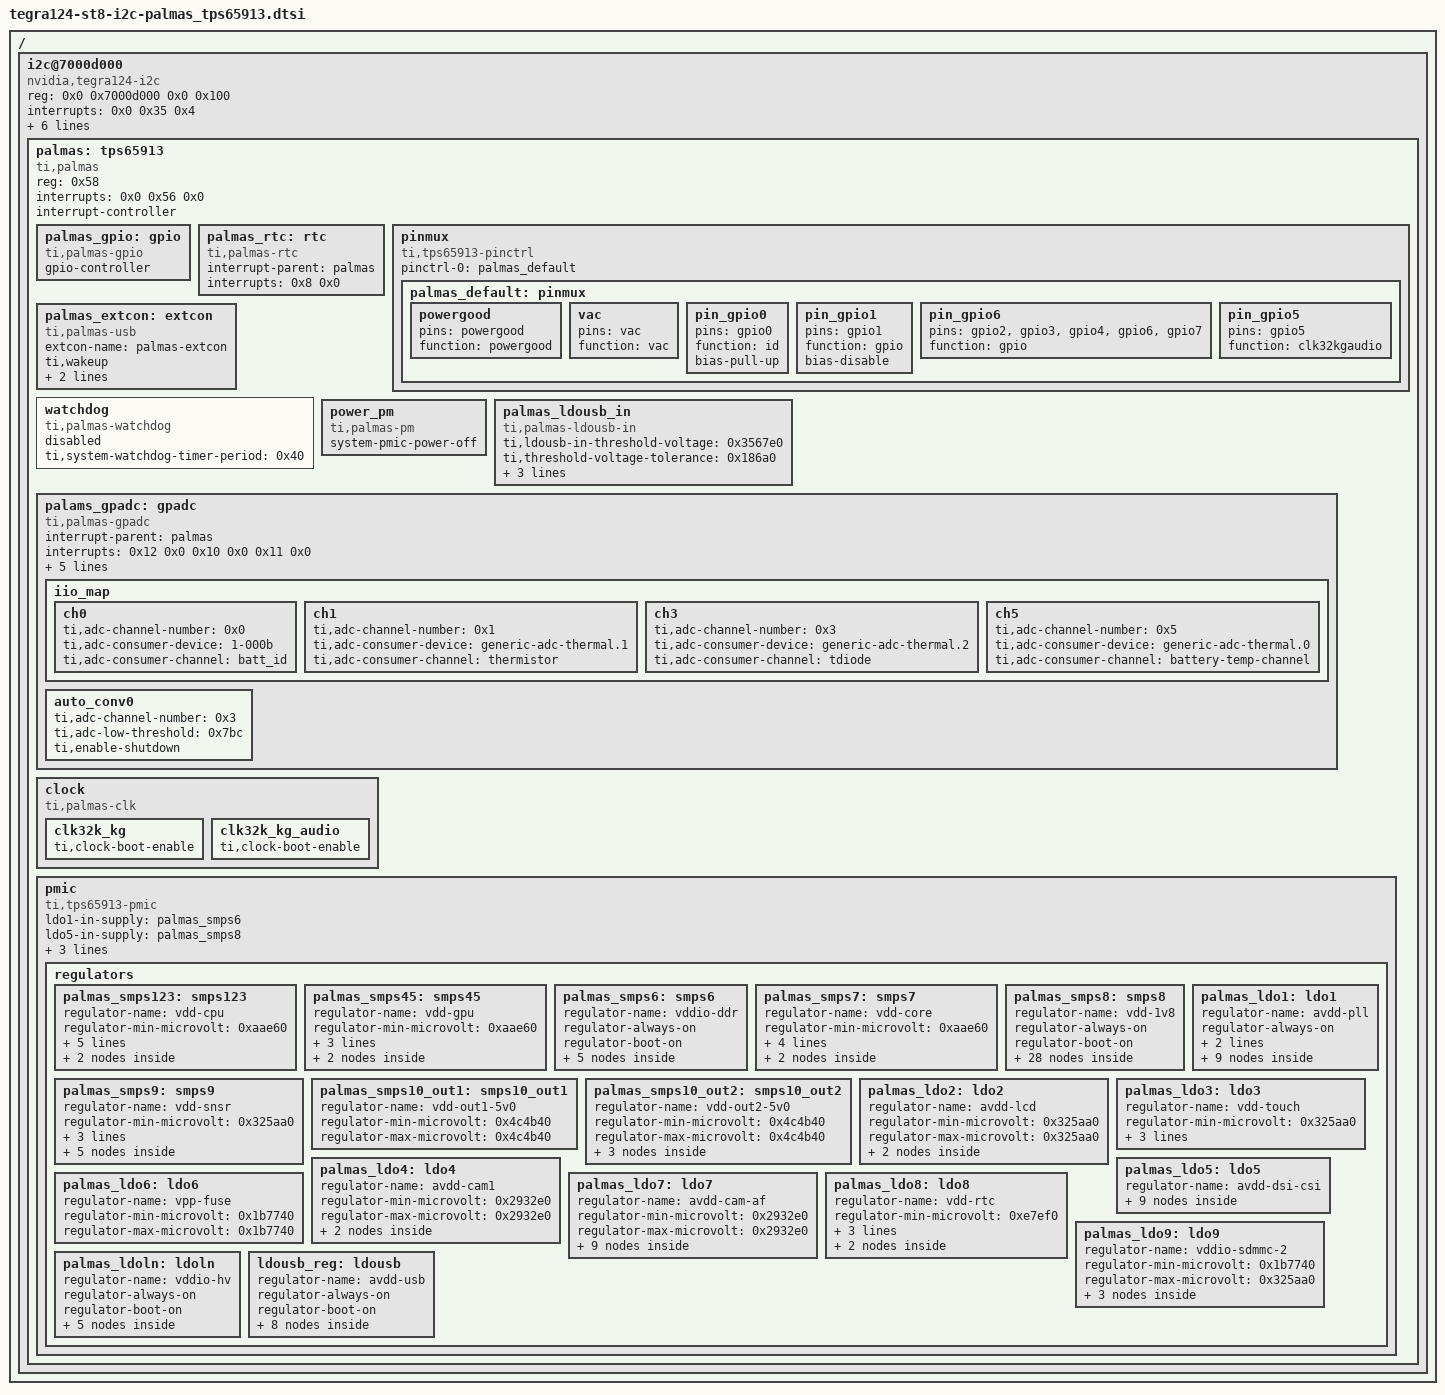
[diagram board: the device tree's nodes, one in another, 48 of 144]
#include <dt-bindings/gpio/tegra-gpio.h>

/ {
    i2c@7000d000 {
        #address-cells = <0x1>;
        #size-cells = <0x0>;
        compatible = "nvidia,tegra124-i2c";
        reg = <0x0 0x7000d000 0x0 0x100>;
        interrupts = <0x0 0x35 0x4>;
        nvidia,require-cldvfs-clock;
        scl-gpio = <0x7 0xce 0x0>;
        sda-gpio = <0x7 0xcf 0x0>;
        nvidia,memory-clients = <0xe>;
        status = "okay";
        clock-frequency = <0x61a80>;
        nvidia,bit-banging-xfer-after-shutdown;
        
        palmas: tps65913 {
            compatible = "ti,palmas";
            reg = <0x58>;
            interrupts = <0x0 0x56 0x0>;
            #interrupt-cells = <0x2>;
            interrupt-controller;
            linux,phandle = <0xb>;
            phandle = <0xb>;
            
            palmas_gpio: gpio {
                compatible = "ti,palmas-gpio";
                gpio-controller;
                #gpio-cells = <0x2>;
                linux,phandle = <0x17>;
                phandle = <0x17>;
            };
            
            palmas_rtc: rtc {
                compatible = "ti,palmas-rtc";
                interrupt-parent = <&palmas>;
                interrupts = <0x8 0x0>;
            };
            
            pinmux {
                compatible = "ti,tps65913-pinctrl";
                pinctrl-names = "default";
                pinctrl-0 = <&palmas_default>;
                
                palmas_default: pinmux {
                    linux,phandle = <0xc>;
                    phandle = <0xc>;
                    
                    powergood {
                        pins = "powergood";
                        function = "powergood";
                    };
                    
                    vac {
                        pins = "vac";
                        function = "vac";
                    };
                    
                    pin_gpio0 {
                        pins = "gpio0";
                        function = "id";
                        bias-pull-up;
                    };
                    
                    pin_gpio1 {
                        pins = "gpio1";
                        function = "gpio";
                        bias-disable;
                    };
                    
                    pin_gpio6 {
                        pins = "gpio2", "gpio3", "gpio4", "gpio6", "gpio7";
                        function = "gpio";
                    };
                    
                    pin_gpio5 {
                        pins = "gpio5";
                        function = "clk32kgaudio";
                    };
                };
            };
            
            palmas_extcon: extcon {
                compatible = "ti,palmas-usb";
                extcon-name = "palmas-extcon";
                ti,wakeup;
                ti,enable-id-detection;
                ti,enable-vbus-detection;
            };
            
            watchdog {
                compatible = "ti,palmas-watchdog";
                ti,system-watchdog-timer-period = <0x40>;
                status = "disabled";
            };
            
            power_pm {
                compatible = "ti,palmas-pm";
                system-pmic-power-off;
            };
            
            palmas_ldousb_in {
                compatible = "ti,palmas-ldousb-in";
                ti,ldousb-in-threshold-voltage = <0x3567e0>;
                ti,threshold-voltage-tolerance = <0x186a0>;
                ti,enable-in1-above-threshold;
                ldousb-in1-supply = <&vdd_ac_bat_reg>;
                ldousb-in2-supply = <&palmas_smps10_out2>;
            };
            
            palams_gpadc: gpadc {
                compatible = "ti,palmas-gpadc";
                interrupt-parent = <&palmas>;
                interrupts = <0x12 0x0 0x10 0x0 0x11 0x0>;
                ti,channel0-current-microamp = <0x5>;
                ti,channel3-current-microamp = <0x190>;
                ti,enable-channel3-dual-current;
                ti,enable-extended-delay;
                ti,auto-conversion-period-ms = <0x1f4>;
                
                iio_map {
                    
                    ch0 {
                        ti,adc-channel-number = <0x0>;
                        ti,adc-consumer-device = "1-000b";
                        ti,adc-consumer-channel = "batt_id";
                    };
                    
                    ch1 {
                        ti,adc-channel-number = <0x1>;
                        ti,adc-consumer-device = "generic-adc-thermal.1";
                        ti,adc-consumer-channel = "thermistor";
                    };
                    
                    ch3 {
                        ti,adc-channel-number = <0x3>;
                        ti,adc-consumer-device = "generic-adc-thermal.2";
                        ti,adc-consumer-channel = "tdiode";
                    };
                    
                    ch5 {
                        ti,adc-channel-number = <0x5>;
                        ti,adc-consumer-device = "generic-adc-thermal.0";
                        ti,adc-consumer-channel = "battery-temp-channel";
                    };
                };
                
                auto_conv0 {
                    ti,adc-channel-number = <0x3>;
                    ti,adc-low-threshold = <0x7bc>;
                    ti,enable-shutdown;
                };
            };
            
            clock {
                compatible = "ti,palmas-clk";
                
                clk32k_kg {
                    ti,clock-boot-enable;
                };
                
                clk32k_kg_audio {
                    ti,clock-boot-enable;
                };
            };
            
            pmic: pmic {
                compatible = "ti,tps65913-pmic", "ti,palmas-pmic";
                ldo1-in-supply = <&palmas_smps6>;
                ldo5-in-supply = <&palmas_smps8>;
                ldo9-in-supply = <&palmas_smps9>;
                ldoln-in-supply = <&palmas_smps10_out2>;
                ldousb-in-supply = <&palmas_smps10_out2>;
                
                regulators {
                    palmas_smps123: smps123 {
                        regulator-name = "vdd-cpu";
                        regulator-min-microvolt = <0xaae60>;
                        regulator-max-microvolt = <0x155cc0>;
                        regulator-always-on;
                        regulator-boot-on;
                        ti,roof-floor = <0x1>;
                        ti,config-flags = <0x8>;
                        
                        consumers {
                            
                            c1 {
                                regulator-consumer-supply = "vdd_cpu";
                            };
                        };
                    };
                    
                    palmas_smps45: smps45 {
                        regulator-name = "vdd-gpu";
                        regulator-min-microvolt = <0xaae60>;
                        regulator-max-microvolt = <0x155cc0>;
                        regulator-init-microvolt = <0xf4240>;
                        regulator-boot-on;
                        
                        consumers {
                            
                            c1 {
                                regulator-consumer-supply = "vdd_gpu";
                            };
                        };
                    };
                    
                    palmas_smps6: smps6 {
                        regulator-name = "vddio-ddr";
                        regulator-always-on;
                        regulator-boot-on;
                        linux,phandle = <0xf>;
                        phandle = <0xf>;
                        
                        consumers {
                            
                            c1 {
                                regulator-consumer-supply = "vddio_ddr";
                            };
                            
                            c2 {
                                regulator-consumer-supply = "vddio_ddr_mclk";
                            };
                            
                            c3 {
                                regulator-consumer-supply = "vddio_ddr3";
                            };
                            
                            c4 {
                                regulator-consumer-supply = "vcore1_ddr3";
                            };
                        };
                    };
                    
                    palmas_smps7: smps7 {
                        regulator-name = "vdd-core";
                        regulator-min-microvolt = <0xaae60>;
                        regulator-max-microvolt = <0x155cc0>;
                        regulator-always-on;
                        regulator-boot-on;
                        ti,roof-floor = <0x3>;
                        
                        consumers {
                            
                            c1 {
                                regulator-consumer-supply = "vdd_core";
                            };
                        };
                    };
                    
                    palmas_smps8: smps8 {
                        regulator-name = "vdd-1v8";
                        regulator-always-on;
                        regulator-boot-on;
                        linux,phandle = <0x8>;
                        phandle = <0x8>;
                        
                        consumers {
                            
                            c1 {
                                regulator-consumer-supply = "dbvdd";
                                regulator-consumer-device = "tegra-snd-rt5639.0";
                            };
                            
                            c2 {
                                regulator-consumer-supply = "avdd";
                                regulator-consumer-device = "tegra-snd-rt5639.0";
                            };
                            
                            c3 {
                                regulator-consumer-supply = "avdd_osc";
                            };
                            
                            c4 {
                                regulator-consumer-supply = "vddio_sys";
                            };
                            
                            c5 {
                                regulator-consumer-supply = "vddio_sys_2";
                            };
                            
                            c6 {
                                regulator-consumer-supply = "vddio_gmi";
                            };
                            
                            c7 {
                                regulator-consumer-supply = "vddio_sdmmc";
                                regulator-consumer-device = "sdhci-tegra.0";
                            };
                            
                            c8 {
                                regulator-consumer-supply = "vddio_sdmmc";
                                regulator-consumer-device = "sdhci-tegra.3";
                            };
                            
                            c9 {
                                regulator-consumer-supply = "avdd_pll_utmip";
                                regulator-consumer-device = "tegra-udc.0";
                            };
                            
                            c10 {
                                regulator-consumer-supply = "avdd_pll_utmip";
                                regulator-consumer-device = "tegra-ehci.0";
                            };
                            
                            c11 {
                                regulator-consumer-supply = "avdd_pll_utmip";
                                regulator-consumer-device = "tegra-ehci.1";
                            };
                            
                            c12 {
                                regulator-consumer-supply = "avdd_pll_utmip";
                                regulator-consumer-device = "tegra-ehci.2";
                            };
                            
                            c14 {
                                regulator-consumer-supply = "vddio_audio";
                            };
                            
                            c15 {
                                regulator-consumer-supply = "vddio_uart";
                            };
                            
                            c16 {
                                regulator-consumer-supply = "vddio_bb";
                            };
                            
                            c17 {
                                regulator-consumer-supply = "vdd_1v8_eeprom";
                            };
                            
                            c18 {
                                regulator-consumer-supply = "vlogic";
                                regulator-consumer-device = "0-0069";
                            };
                            
                            c19 {
                                regulator-consumer-supply = "vdd";
                                regulator-consumer-device = "0-0069";
                            };
                            
                            c20 {
                                regulator-consumer-supply = "dmicvdd";
                                regulator-consumer-device = "tegra-snd-rt5639.0";
                            };
                            
                            c21 {
                                regulator-consumer-supply = "dmicvdd";
                                regulator-consumer-device = "tegra-snd-rt5645.0";
                            };
                            
                            c22 {
                                regulator-consumer-supply = "vid";
                                regulator-consumer-device = "0-000d";
                            };
                            
                            c23 {
                                regulator-consumer-supply = "pwrdet_nand";
                            };
                            
                            c24 {
                                regulator-consumer-supply = "pwrdet_sdmmc1";
                            };
                            
                            c25 {
                                regulator-consumer-supply = "pwrdet_sdmmc4";
                            };
                            
                            c26 {
                                regulator-consumer-supply = "pwrdet_audio";
                            };
                            
                            c27 {
                                regulator-consumer-supply = "pwrdet_uart";
                            };
                            
                            c28 {
                                regulator-consumer-supply = "pwrdet_bb";
                            };
                        };
                    };
                    
                    palmas_smps9: smps9 {
                        regulator-name = "vdd-snsr";
                        regulator-min-microvolt = <0x325aa0>;
                        regulator-max-microvolt = <0x325aa0>;
                        regulator-always-on;
                        regulator-boot-on;
                        linux,phandle = <0x9>;
                        phandle = <0x9>;
                        
                        consumers {
                            
                            c1 {
                                regulator-consumer-supply = "vddio_sd_slot";
                                regulator-consumer-device = "sdhci-tegra.3";
                            };
                            
                            c2 {
                                regulator-consumer-supply = "vdd";
                                regulator-consumer-device = "0-000d";
                            };
                            
                            c3 {
                                regulator-consumer-supply = "vdd";
                                regulator-consumer-device = "0-004c";
                            };
                            
                            c4 {
                                regulator-consumer-supply = "vdd";
                                regulator-consumer-device = "0-004d";
                            };
                        };
                    };
                    
                    palmas_smps10_out1: smps10_out1 {
                        regulator-name = "vdd-out1-5v0";
                        regulator-min-microvolt = <0x4c4b40>;
                        regulator-max-microvolt = <0x4c4b40>;
                        linux,phandle = <0x18>;
                        phandle = <0x18>;
                    };
                    
                    palmas_smps10_out2: smps10_out2 {
                        regulator-name = "vdd-out2-5v0";
                        regulator-min-microvolt = <0x4c4b40>;
                        regulator-max-microvolt = <0x4c4b40>;
                        linux,phandle = <0xe>;
                        phandle = <0xe>;
                        
                        consumers {
                            
                            c1 {
                                regulator-consumer-supply = "spkvdd";
                                regulator-consumer-device = "tegra-snd-rt5639.0";
                            };
                            
                            c2 {
                                regulator-consumer-supply = "spkvdd";
                                regulator-consumer-device = "tegra-snd-rt5645.0";
                            };
                        };
                    };
                    
                    palmas_ldo1: ldo1 {
                        regulator-name = "avdd-pll";
                        regulator-always-on;
                        regulator-boot-on;
                        ti,roof-floor = <0x3>;
                        
                        consumers {
                            
                            c1 {
                                regulator-consumer-supply = "avdd_pll_m";
                            };
                            
                            c2 {
                                regulator-consumer-supply = "avdd_pll_ap_c2_c3";
                            };
                            
                            c3 {
                                regulator-consumer-supply = "avdd_pll_cud2dpd";
                            };
                            
                            c4 {
                                regulator-consumer-supply = "avdd_pll_c4";
                            };
                            
                            c5 {
                                regulator-consumer-supply = "vddio_ddr_hs";
                            };
                            
                            c6 {
                                regulator-consumer-supply = "avdd_pll_erefe";
                            };
                            
                            c7 {
                                regulator-consumer-supply = "avdd_pll_cg";
                            };
                            
                            c8 {
                                regulator-consumer-supply = "avdd_pll_x";
                            };
                        };
                    };
                    
                    palmas_ldo2: ldo2 {
                        regulator-name = "avdd-lcd";
                        regulator-min-microvolt = <0x325aa0>;
                        regulator-max-microvolt = <0x325aa0>;
                        
                        consumers {
                            
                            c1 {
                                regulator-consumer-supply = "avdd_lcd";
                                regulator-consumer-device = "tegradc.0";
                            };
                        };
                    };
                    
                    palmas_ldo3: ldo3 {
                        regulator-name = "vdd-touch";
                        regulator-min-microvolt = <0x325aa0>;
                        regulator-max-microvolt = <0x325aa0>;
                        regulator-enable-ramp-delay = <0xbb8>;
                        ti,disable-pull-down;
                        linux,phandle = <0x19>;
                        phandle = <0x19>;
                    };
                    
                    palmas_ldo4: ldo4 {
                        regulator-name = "avdd-cam1";
                        regulator-min-microvolt = <0x2932e0>;
                        regulator-max-microvolt = <0x2932e0>;
                        
                        consumers {
                            
                            c1 {
                                regulator-consumer-supply = "avdd_ov5693";
                                regulator-consumer-device = "2-0010";
                            };
                        };
                    };
                    
                    palmas_ldo5: ldo5 {
                        regulator-name = "avdd-dsi-csi";
                        linux,phandle = <0x14>;
                        phandle = <0x14>;
                        
                        consumers {
                            
                            c1 {
                                regulator-consumer-supply = "vddio_hsic";
                                regulator-consumer-device = "tegra-ehci.1";
                            };
                            
                            c2 {
                                regulator-consumer-supply = "vddio_hsic";
                                regulator-consumer-device = "tegra-ehci.2";
                            };
                            
                            c4 {
                                regulator-consumer-supply = "avdd_dsi_csi";
                                regulator-consumer-device = "tegradc.0";
                            };
                            
                            c5 {
                                regulator-consumer-supply = "avdd_dsi_csi";
                                regulator-consumer-device = "tegradc.1";
                            };
                            
                            c6 {
                                regulator-consumer-supply = "avdd_dsi_csi";
                                regulator-consumer-device = "vi.0";
                            };
                            
                            c7 {
                                regulator-consumer-supply = "avdd_dsi_csi";
                                regulator-consumer-device = "vi.1";
                            };
                            
                            c8 {
                                regulator-consumer-supply = "vdd_lcd_bl";
                                regulator-consumer-device = "tegradc.0";
                            };
                            
                            c9 {
                                regulator-consumer-supply = "pwrdet_mipi";
                            };
                        };
                    };
                    
                    palmas_ldo6: ldo6 {
                        regulator-name = "vpp-fuse";
                        regulator-min-microvolt = <0x1b7740>;
                        regulator-max-microvolt = <0x1b7740>;
                        linux,phandle = <0x12>;
                        phandle = <0x12>;
                    };
                    
                    palmas_ldo7: ldo7 {
                        regulator-name = "avdd-cam-af";
                        regulator-min-microvolt = <0x2932e0>;
                        regulator-max-microvolt = <0x2932e0>;
                        
                        consumers {
                            
                            c1 {
                                regulator-consumer-supply = "avdd_af1_cam";
                            };
                            
                            c2 {
                                regulator-consumer-supply = "avdd_cam2_cam";
                            };
                            
                            c3 {
                                regulator-consumer-supply = "vdd_af1";
                                regulator-consumer-device = "2-0010";
                            };
                            
                            c4 {
                                regulator-consumer-supply = "vdd";
                                regulator-consumer-device = "2-000c";
                            };
                            
                            c5 {
                                regulator-consumer-supply = "vana";
                                regulator-consumer-device = "2-0048";
                            };
                            
                            c6 {
                                regulator-consumer-supply = "vana";
                                regulator-consumer-device = "2-0036";
                            };
                            
                            c7 {
                                regulator-consumer-supply = "vin";
                                regulator-consumer-device = "2-0030";
                            };
                            
                            c8 {
                                regulator-consumer-supply = "vana";
                                regulator-consumer-device = "2-0010";
                            };
                        };
                    };
                    
                    palmas_ldo8: ldo8 {
                        regulator-name = "vdd-rtc";
                        regulator-min-microvolt = <0xe7ef0>;
                        regulator-max-microvolt = <0xe7ef0>;
                        regulator-always-on;
                        regulator-boot-on;
                        
                        consumers {
                            
                            c1 {
                                regulator-consumer-supply = "vdd_rtc";
                            };
                        };
                    };
                    
                    palmas_ldo9: ldo9 {
                        regulator-name = "vddio-sdmmc-2";
                        regulator-min-microvolt = <0x1b7740>;
                        regulator-max-microvolt = <0x325aa0>;
                        
                        consumers {
                            
                            c1 {
                                regulator-consumer-supply = "vddio_sdmmc";
                                regulator-consumer-device = "sdhci-tegra.2";
                            };
                            
                            c2 {
                                regulator-consumer-supply = "pwrdet_sdmmc3";
                            };
                        };
                    };
                    
                    palmas_ldoln: ldoln {
                        regulator-name = "vddio-hv";
                        regulator-always-on;
                        regulator-boot-on;
                        
                        consumers {
                            
                            c1 {
                                regulator-consumer-supply = "vddio_hv";
                                regulator-consumer-device = "tegradc.1";
                            };
                            
                            c2 {
                                regulator-consumer-supply = "avdd_hdmi";
                                regulator-consumer-device = "tegradc.1";
                            };
                            
                            c3 {
                                regulator-consumer-supply = "pwrdet_hv";
                            };
                            
                            c4 {
                                regulator-consumer-supply = "vddio_pex_ctl";
                                regulator-consumer-device = "tegra-pcie";
                            };
                        };
                    };
                    
                    ldousb_reg: ldousb {
                        regulator-name = "avdd-usb";
                        regulator-always-on;
                        regulator-boot-on;
                        linux,phandle = <0x13>;
                        phandle = <0x13>;
                        
                        consumers {
                            
                            c1 {
                                regulator-consumer-supply = "pwrdet_pex_ctl";
                            };
                            
                            c2 {
                                regulator-consumer-supply = "avdd_usb";
                                regulator-consumer-device = "tegra-udc.0";
                            };
                            
                            c3 {
                                regulator-consumer-supply = "avdd_usb";
                                regulator-consumer-device = "tegra-ehci.0";
                            };
                            
                            c4 {
                                regulator-consumer-supply = "avdd_usb";
                                regulator-consumer-device = "tegra-ehci.1";
                            };
                            
                            c5 {
                                regulator-consumer-supply = "avdd_usb";
                                regulator-consumer-device = "tegra-ehci.2";
                            };
                            
                            c7 {
                                regulator-consumer-supply = "hvdd_pex";
                                regulator-consumer-device = "tegra-pcie";
                            };
                            
                            c8 {
                                regulator-consumer-supply = "hvdd_pex_pll_e";
                                regulator-consumer-device = "tegra-pcie";
                            };
                        };
                    };
                };
            };
        };
    };
};
